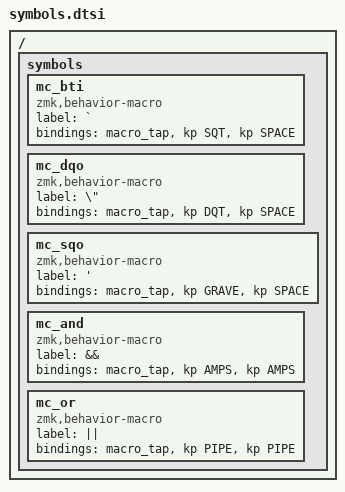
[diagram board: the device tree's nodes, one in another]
/*
*
* Copyright (c) 2022 Rafael Romão
* SPDX-License-Identifier: MIT
*
*/

#include <behaviors.dtsi>
#include <dt-bindings/zmk/keys.h>
#include <dt-bindings/zmk/bt.h>

/ {
    symbols {
        mc_bti: mc_bti {
            label = "`";
            compatible = "zmk,behavior-macro";
            #binding-cells = <0>;
            bindings = <&macro_tap &kp SQT &kp SPACE>;
        };
        mc_dqo: mc_dqo {
            label = "\"";
            compatible = "zmk,behavior-macro";
            #binding-cells = <0>;
            bindings = <&macro_tap &kp DQT &kp SPACE>;
        };
        mc_sqo: mc_sqo {
            label = "'";
            compatible = "zmk,behavior-macro";
            #binding-cells = <0>;
            bindings = <&macro_tap &kp GRAVE &kp SPACE>;
        };
        mc_and: mc_and {
            label = "&&";
            compatible = "zmk,behavior-macro";
            #binding-cells = <0>;
            bindings = <&macro_tap &kp AMPS &kp AMPS>;
        };
        mc_or: mc_or {
            label = "||";
            compatible = "zmk,behavior-macro";
            #binding-cells = <0>;
            bindings = <&macro_tap &kp PIPE &kp PIPE>;
        };
    };
};


